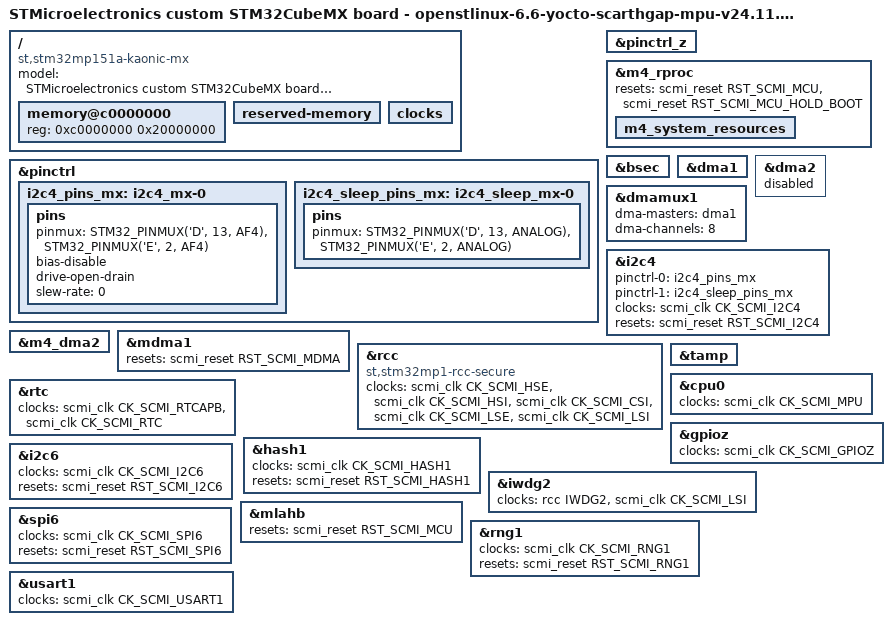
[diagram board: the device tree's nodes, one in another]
// SPDX-License-Identifier: (GPL-2.0-or-later OR BSD-3-Clause)
/*
 * Copyright (C) 2025, STMicroelectronics - All Rights Reserved
 * Author: STM32CubeMX code generation for STMicroelectronics.
 */

/* For more information on Device Tree configuration, please refer to
 * https://wiki.st.com/stm32mpu/wiki/Category:Device_tree_configuration
 */

/dts-v1/;

#include <dt-bindings/pinctrl/stm32-pinfunc.h>
#include "stm32mp151.dtsi"
#include "stm32mp15xa.dtsi"
#include "stm32mp15xxab-pinctrl.dtsi"
#include "stm32mp15-m4-srm.dtsi"

/* USER CODE BEGIN includes */
#include "stm32mp15-scmi.dtsi"
/* USER CODE END includes */

/ {
	model = "STMicroelectronics custom STM32CubeMX board - openstlinux-6.6-yocto-scarthgap-mpu-v24.11.06";
	compatible = "st,stm32mp151a-kaonic-mx", "st,stm32mp151";

	memory@c0000000 {
		device_type = "memory";
		reg = <0xc0000000 0x20000000>;

		/* USER CODE BEGIN memory */
		/* USER CODE END memory */
	};

	reserved-memory {
		#address-cells = <1>;
		#size-cells = <1>;
		ranges;

		/* USER CODE BEGIN reserved-memory */
		/* USER CODE END reserved-memory */
	};

	/* USER CODE BEGIN root */
	/* USER CODE END root */

	clocks{

		/* USER CODE BEGIN clocks */
		/* USER CODE END clocks */
	};

}; /*root*/

&pinctrl {

	i2c4_pins_mx: i2c4_mx-0 {
		pins {
			pinmux = <STM32_PINMUX('D', 13, AF4)>, /* I2C4_SDA */
					 <STM32_PINMUX('E', 2, AF4)>; /* I2C4_SCL */
			bias-disable;
			drive-open-drain;
			slew-rate = <0>;
		};
	};

	i2c4_sleep_pins_mx: i2c4_sleep_mx-0 {
		pins {
			pinmux = <STM32_PINMUX('D', 13, ANALOG)>, /* I2C4_SDA */
					 <STM32_PINMUX('E', 2, ANALOG)>; /* I2C4_SCL */
		};
	};

	/* USER CODE BEGIN pinctrl */
	/* USER CODE END pinctrl */
};

&pinctrl_z {

	/* USER CODE BEGIN pinctrl_z */
	/* USER CODE END pinctrl_z */
};

&m4_rproc{
	status = "okay";

	/* USER CODE BEGIN m4_rproc */
	/* USER CODE END m4_rproc */

	m4_system_resources{
		status = "okay";

		/* USER CODE BEGIN m4_system_resources */
		/* USER CODE END m4_system_resources */
	};
};

&bsec {
	status = "okay";

	/* USER CODE BEGIN bsec */
	/* USER CODE END bsec */
};

&dma1 {
	status = "okay";

	/* USER CODE BEGIN dma1 */
	/* USER CODE END dma1 */
};

&dma2 {
	status = "disabled";

	/* USER CODE BEGIN dma2 */
	/* USER CODE END dma2 */
};

&dmamux1 {
	status = "okay";

	dma-masters = <&dma1>;
	dma-channels = <8>;

	/* USER CODE BEGIN dmamux1 */
	/* USER CODE END dmamux1 */
};

&i2c4 {
	pinctrl-names = "default", "sleep";
	pinctrl-0 = <&i2c4_pins_mx>;
	pinctrl-1 = <&i2c4_sleep_pins_mx>;
	status = "okay";

	/* USER CODE BEGIN i2c4 */
	/* USER CODE END i2c4 */
};

&m4_dma2 {
	status = "okay";

	/* USER CODE BEGIN m4_dma2 */
	/* USER CODE END m4_dma2 */
};

&mdma1 {
	status = "okay";

	/* USER CODE BEGIN mdma1 */
	/* USER CODE END mdma1 */
};

&rcc {
	status = "okay";

	/* USER CODE BEGIN rcc */
	/* USER CODE END rcc */
};

&rtc {
	status = "okay";

	/* USER CODE BEGIN rtc */
	/* USER CODE END rtc */
};

&tamp {
	status = "okay";

	/* USER CODE BEGIN tamp */
	/* USER CODE END tamp */
};

/* USER CODE BEGIN addons */

&cpu0 {
	clocks = <&scmi_clk CK_SCMI_MPU>;
};

&gpioz {
	clocks = <&scmi_clk CK_SCMI_GPIOZ>;
};

&hash1 {
	clocks = <&scmi_clk CK_SCMI_HASH1>;
	resets = <&scmi_reset RST_SCMI_HASH1>;
};

&i2c4 {
	clocks = <&scmi_clk CK_SCMI_I2C4>;
	resets = <&scmi_reset RST_SCMI_I2C4>;
};

&i2c6 {
	clocks = <&scmi_clk CK_SCMI_I2C6>;
	resets = <&scmi_reset RST_SCMI_I2C6>;
};

&iwdg2 {
	clocks = <&rcc IWDG2>, <&scmi_clk CK_SCMI_LSI>;
};

&m4_rproc {
	resets = <&scmi_reset RST_SCMI_MCU>,
		 <&scmi_reset RST_SCMI_MCU_HOLD_BOOT>;
	reset-names = "mcu_rst", "hold_boot";
	/delete-property/ st,syscfg-holdboot;
};

&mdma1 {
	resets = <&scmi_reset RST_SCMI_MDMA>;
};

&mlahb {
	resets = <&scmi_reset RST_SCMI_MCU>;
};

&rcc {
	compatible = "st,stm32mp1-rcc-secure", "syscon";
	clock-names = "hse", "hsi", "csi", "lse", "lsi";
	clocks = <&scmi_clk CK_SCMI_HSE>,
		 <&scmi_clk CK_SCMI_HSI>,
		 <&scmi_clk CK_SCMI_CSI>,
		 <&scmi_clk CK_SCMI_LSE>,
		 <&scmi_clk CK_SCMI_LSI>;
};

&rng1 {
	clocks = <&scmi_clk CK_SCMI_RNG1>;
	resets = <&scmi_reset RST_SCMI_RNG1>;
};

&rtc {
	clocks = <&scmi_clk CK_SCMI_RTCAPB>, <&scmi_clk CK_SCMI_RTC>;
};

&spi6 {
	clocks = <&scmi_clk CK_SCMI_SPI6>;
	resets = <&scmi_reset RST_SCMI_SPI6>;
};

&usart1 {
	clocks = <&scmi_clk CK_SCMI_USART1>;
};

/* USER CODE END addons */

